# STM32WBA52 register map
File version: 1.3
CPU: CM33 r0p1, little endian, MPU, FPU, 4 interrupt priority bits
Registers are 32-bit, read-write, reset 0x0 unless marked. A register's access mark holds for its fields unless they carry their own. Offsets are from the block's base; [hi:lo] are bit positions; {n}, {i} and the like mark numbered series.

## GPIOB — General-purpose I/Os
Base 0x42020400
Same registers: SEC_GPIOB 0x52020400
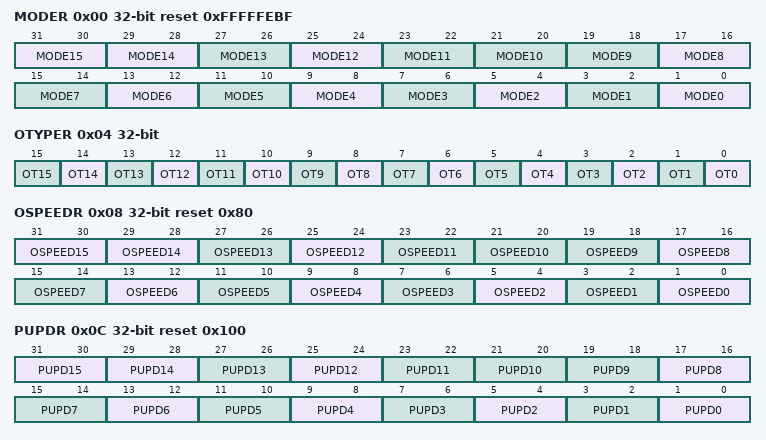
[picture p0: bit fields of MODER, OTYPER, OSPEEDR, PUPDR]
0x00 MODER reset 0xFFFFFEBF — GPIO port B mode register
  [all] fields
    0=Input mode; 1=Output (General purpose output mode); 2=Alternate function mode; 3=Analog mode
  [31:30] MODE15 — Port configuration I/O pin 15 These bits are written by software to configure the I/O mode. Access can be protected by GPIOB SEC15.
  [2n+1:2n] MODE{n} (n=11..14) — Port configuration I/O pin {n}
  [21:20] MODE10 — Port configuration I/O pin 10 Note that bits 21:20 are reserved on STM32WBA55xx devices.
  [2n+1:2n] MODE{n} (n=0..9) — Port configuration I/O pin {n}
0x04 OTYPER — GPIO port B output type register
  [all] fields
    0=PushPull (Output push-pull (reset state)); 1=OpenDrain (Output open-drain)
  [n] OT{n} (n=0..15) — Port configuration I/O pin y These bits are written by software to configure the I/O output type. Access can be protected by GPIOB SECy. Note that bit 10 is reserved on STM32WBA55xx devices.
0x08 OSPEEDR reset 0x80 — GPIO port B output speed register
  [all] fields
    0=LowSpeed; 1=MediumSpeed; 2=HighSpeed; 3=VeryHighSpeed
  [31:30] OSPEED15 — Port configuration I/O pin 15 These bits are written by software to configure the I/O output speed. Access can be protected by GPIOB SEC15. Note: Refer to the device datasheet for the frequency specifications and the power supply and load conditions for each speed.
  [2n+1:2n] OSPEED{n} (n=11..14) — Port configuration I/O pin {n}
  [21:20] OSPEED10 — Port configuration I/O pin 10 Note that bits 21:20 are reserved on STM32WBA55xx devices.
  [2n+1:2n] OSPEED{n} (n=0..9) — Port configuration I/O pin {n}
0x0C PUPDR reset 0x100 — GPIO port B pull-up/pull-down register
  [all] fields
    0=Floating (No pull-up, pull-down); 1=PullUp; 2=PullDown
  [31:30] PUPD15 — Port configuration I/O pin 15 These bits are written by software to configure the I/O pull-up or pull-down Access can be protected by GPIOB SEC15.
  [2n+1:2n] PUPD{n} (n=11..14) — Port configuration I/O pin {n}
  [21:20] PUPD10 — Port configuration I/O pin 10 Note that bits 21:20 are reserved on STM32WBA55xx devices.
  [2n+1:2n] PUPD{n} (n=0..9) — Port configuration I/O pin {n}
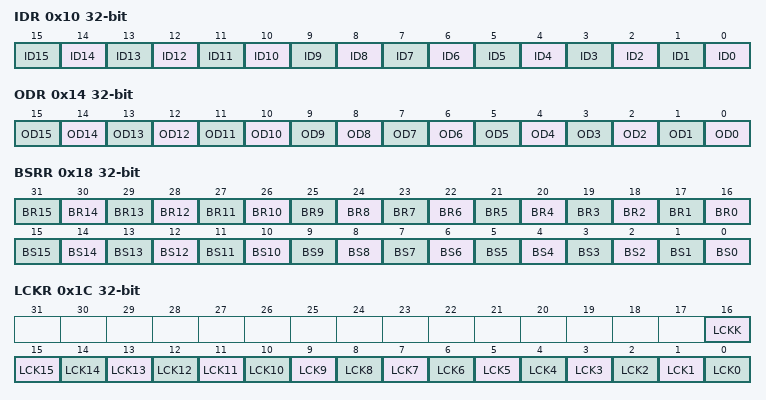
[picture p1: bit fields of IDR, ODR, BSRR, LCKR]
0x10 IDR ro (reset mask 0xFFFF0000) — GPIO port B input data register
  [all] fields
    0=Low (Input is logic low); 1=High (Input is logic high)
  [n] ID{n} (n=0..15) — Port input data I/O pin y These bits are read-only. They contain the input value of the corresponding I/O port. Access can be protected by GPIOB SECy. Note that bit 10 is reserved on STM32WBA55xx devices.
0x14 ODR — GPIO port B output data register
  [all] fields
    0=Low (Set output to logic low); 1=High (Set output to logic high)
  [n] OD{n} (n=0..15) — Port output data I/O pin y These bits can be read and written by software. Access can be protected by GPIOB SECy. Note that bit 10 is reserved on STM32WBA55xx devices. Note: For atomic bit set/reset, the OD bits can be individually set and/or reset by writing to the GPIOB_BSRR or GPIOB_BRR registers.
0x18 BSRR wo — GPIO port B bit set/reset register
  [n+16] BR{n} (n=0..15) — Port reset I/O pin y These bits are write-only. A read to these bits returns the value 0. Access can be protected by GPIOB SECy. Note that bit 26 is reserved on STM32WBA55xx devices. Note: If both BSy and BRy are set, BSy has priority.
    1=Resets the corresponding ODx bit
  [n] BS{n} (n=0..15) — Port set I/O pin y These bits are write-only. A read to these bits returns the value 0. Access can be protected by GPIOB SECy. Note that bit 10 is reserved on STM32WBA55xx devices.
    1=Set (Sets the corresponding ODx bit)
0x1C LCKR — GPIO port B configuration lock register
  [16] LCKK — Lock key This bit can be read any time. It can only be modified using the lock key write sequence. Access can be protected by any GPIOB SECy. - LOCK key write sequence: WR LCKR[16] = 1 + LCKR[15:0] WR LCKR[16] = 0 + LCKR[15:0] WR LCKR[16] = 1 + LCKR[15:0] - LOCK key read RD LCKR[16] = 1 (this read operation is optional but it confirms that the lock is active) Note: During the LOCK key write sequence, the value of LCKR[15:0] must not change. Note: Any error in the lock sequence aborts the LOCK. Note: After the first LOCK sequence on any bit of the port, any read access on the LCKK bit returns 1 until the next MCU reset or peripheral reset.
    0=NotActive (Port configuration lock key not active); 1=Active (Port configuration lock key active)
  [n] LCK{n} (n=0..15) — Port lock I/O pin y These bits are read/write but can only be written when the LCKK bit is 0 Access can be protected by GPIOB SECy. Note that bit 10 is reserved on STM32WBA55xx devices.
    0=Unlocked (Port configuration not locked); 1=Locked (Port configuration locked)
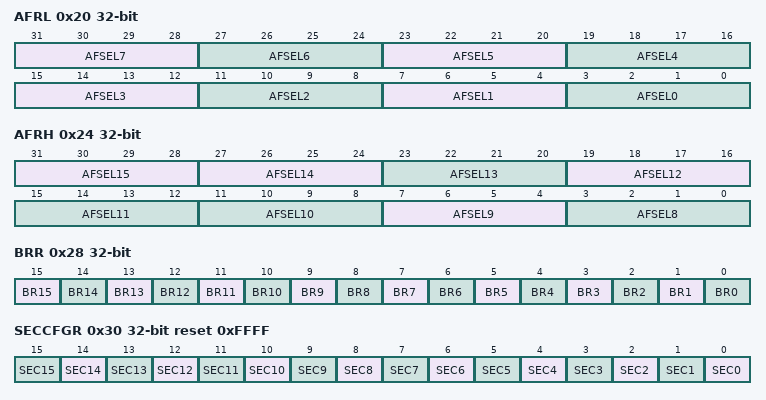
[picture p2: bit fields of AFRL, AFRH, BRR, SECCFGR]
0x20 AFRL — GPIO port B alternate function low register
  [all] fields
    {v}=AF{v} (v=0..15)
  [31:28] AFSEL7 — Alternate function selection for port I/O pin 7 These bits are written by software to configure alternate function I/Os. Access can be protected by GPIOB SEC7.
  [4n+3:4n] AFSEL{n} (n=0..6) — Alternate function selection for port I/O pin {n}
0x24 AFRH — GPIO port B alternate function high register
  [all] fields
    {v}=AF{v} (v=0..15)
  [31:28] AFSEL15 — Alternate function selection for port I/O pin 15 These bits are written by software to configure alternate function I/Os. Access can be protected by GPIOB SEC15.
  [4n-29:4n-32] AFSEL{n} (n=11..14) — Alternate function selection for port I/O pin {n}
  [11:8] AFSEL10 — Alternate function selection for port I/O pin 10 Note that bit 11:8 are reserved on STM32WBA55xx devices.
  [7:4] AFSEL9 — Alternate function selection for port I/O pin 9
  [3:0] AFSEL8 — Alternate function selection for port I/O pin 8
0x28 BRR wo — GPIO port B bit reset register
  [n] BR{n} (n=1..15) — Port reset I/O pin y These bits are write-only. A read to these bits returns the value 0. Access can be protected by GPIOB SECy. Note that bit 10 is reserved on STM32WBA55xx devices.
    1=Resets the corresponding ODx bit
  [0] BR0 — Port reset I/O pin y These bits are write-only. A read to these bits returns the value 0. Access can be protected by GPIOB SECy. Note that bit 10 is reserved on STM32WBA55xx devices.
    0=No action on the corresponding ODx bit; 1=Reset the ODx bit
0x30 SECCFGR wo reset 0xFFFF — GPIO port B secure configuration register
  [all] fields
    0=NonSecure (The I/O pin is non-secure); 1=Secure (The I/O pin is secure)
  [n] SEC{n} (n=0..15) — I/O pin of port secure bit enable y These bits are written by software to enabled the security I/O port pin. Note that bit 10 is reserved on STM32WBA55xx devices.
